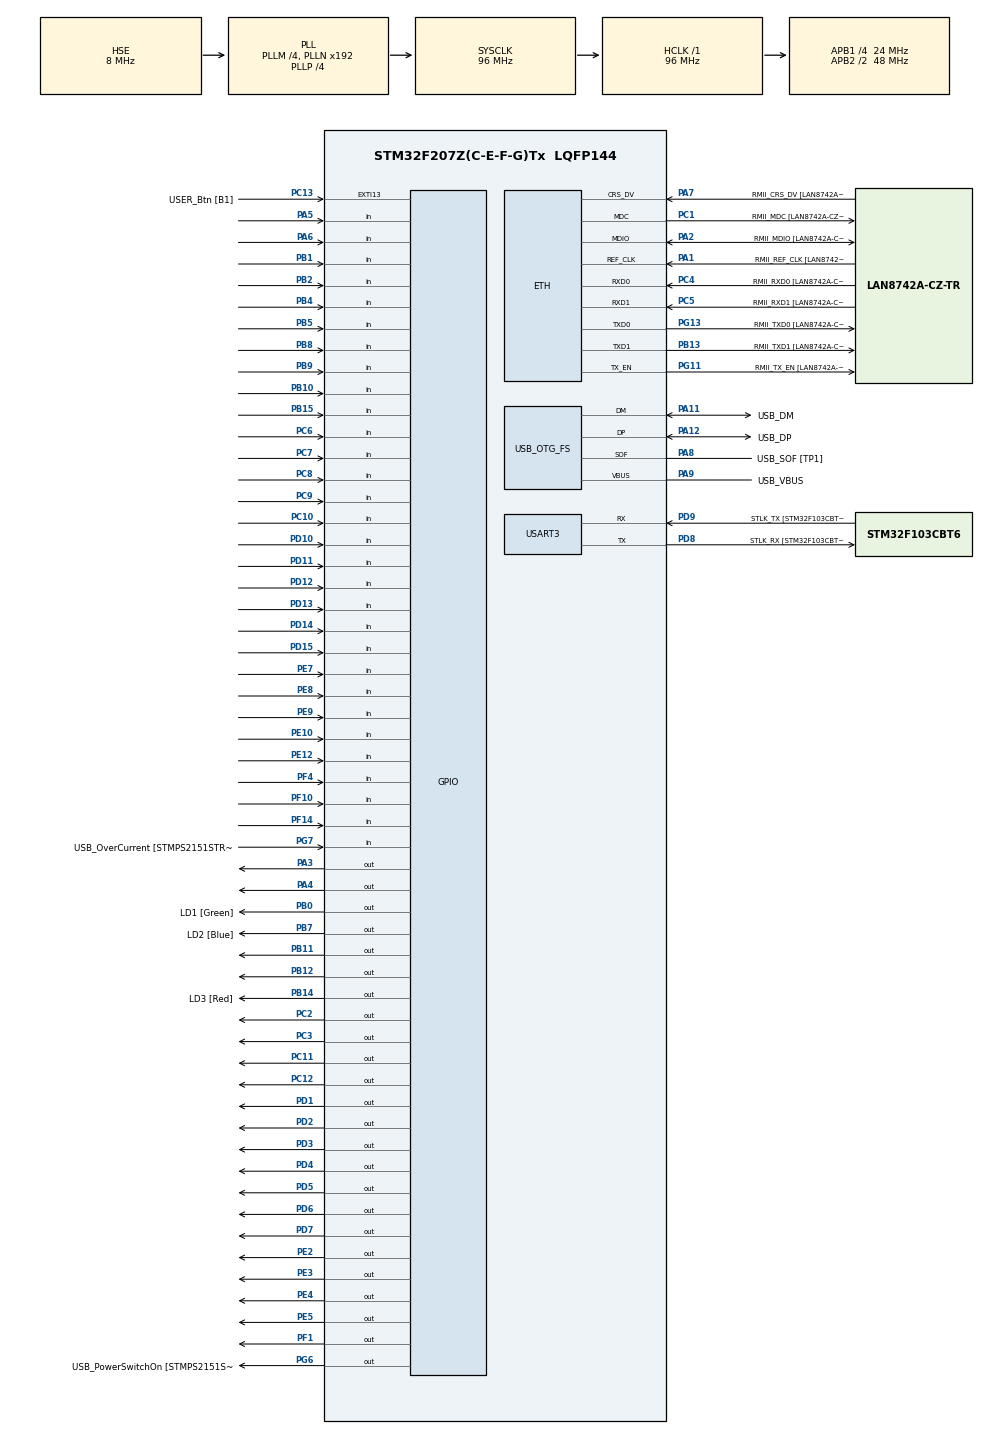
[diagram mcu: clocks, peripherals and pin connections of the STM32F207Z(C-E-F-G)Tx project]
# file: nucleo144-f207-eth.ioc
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ETH.MACAddr=00\:15\:7E\:00\:00\:00
ETH.MediaInterface=ETH_MEDIA_INTERFACE_RMII
ETH.PHY_Name=LAN8742A_PHY_ADDRESS
ETH.PHY_Value=0
ETH.PhyAddress=0
FREERTOS.Tasks01=defaultTask,0,512,StartDefaultTask,Default,NULL,Dynamic,NULL,NULL
FREERTOS.configMINIMAL_STACK_SIZE=256
FREERTOS.configUSE_NEWLIB_REENTRANT=1
LWIP.CMSIS_VERSION-Enabled=1
LWIP.GATEWAY_ADDRESS=000.000.000.000
LWIP.IP_ADDRESS=192.168.001.207
LWIP.LWIP_DHCP=0
LWIP.NETMASK_ADDRESS=255.255.255.000
LWIP.Version=v2.0.3_Cube
Mcu.Family=STM32F2
Mcu.Name=STM32F207Z(C-E-F-G)Tx
Mcu.Package=LQFP144
NVIC.ETH_IRQn=true\:5\:0\:false\:false\:true\:true\:false\:true
NVIC.PriorityGroup=NVIC_PRIORITYGROUP_4
NVIC.TIM1_UP_TIM10_IRQn=true\:15\:0\:false\:false\:true\:false\:false\:true
NVIC.TimeBase=TIM1_UP_TIM10_IRQn
NVIC.TimeBaseIP=TIM1
PA1.GPIO_Label=RMII_REF_CLK [LAN8742A-CZ-TR_REFCLK0]
PA1.Mode=RMII
PA1.Signal=ETH_REF_CLK
PA10.GPIO_Label=USB_ID
PA10.Signal=USB_OTG_FS_ID
PA11.GPIO_Label=USB_DM
PA11.Mode=Device_Only
PA11.Signal=USB_OTG_FS_DM
PA12.GPIO_Label=USB_DP
PA12.Mode=Device_Only
PA12.Signal=USB_OTG_FS_DP
PA13.GPIO_Label=TMS
PA13.Mode=Serial_Wire
PA13.Signal=SYS_JTMS-SWDIO
PA14.GPIO_Label=TCK
PA14.Mode=Serial_Wire
PA14.Signal=SYS_JTCK-SWCLK
PA2.GPIO_Label=RMII_MDIO [LAN8742A-CZ-TR_MDIO]
PA2.Mode=RMII
PA2.Signal=ETH_MDIO
PA3.Signal=GPIO_Output
PA4.Signal=GPIO_Output
PA5.GPIO_PuPd=GPIO_PULLDOWN
PA5.Signal=GPIO_Input
PA6.GPIO_PuPd=GPIO_PULLDOWN
PA6.Signal=GPIO_Input
PA7.GPIO_Label=RMII_CRS_DV [LAN8742A-CZ-TR_CRS_DV]
PA7.Mode=RMII
PA7.Signal=ETH_CRS_DV
PA8.GPIO_Label=USB_SOF [TP1]
PA8.Mode=Activate_SOF_FS
PA8.Signal=USB_OTG_FS_SOF
PA9.GPIO_Label=USB_VBUS
PA9.Mode=Activate_VBUS
PA9.Signal=USB_OTG_FS_VBUS
PB0.GPIO_Label=LD1 [Green]
PB0.Signal=GPIO_Output
PB1.GPIO_PuPd=GPIO_PULLDOWN
PB1.Signal=GPIO_Input
PB10.GPIO_PuPd=GPIO_PULLDOWN
PB10.Signal=GPIO_Input
PB11.Signal=GPIO_Output
PB12.Signal=GPIO_Output
PB13.GPIO_Label=RMII_TXD1 [LAN8742A-CZ-TR_TXD1]
PB13.Mode=RMII
PB13.Signal=ETH_TXD1
PB14.GPIO_Label=LD3 [Red]
PB14.Signal=GPIO_Output
PB15.GPIO_PuPd=GPIO_PULLDOWN
PB15.Signal=GPIO_Input
PB2.GPIO_PuPd=GPIO_PULLDOWN
PB2.Signal=GPIO_Input
PB3.GPIO_Label=SWO
PB3.Signal=SYS_JTDO-SWO
PB4.GPIO_PuPd=GPIO_PULLDOWN
PB4.Signal=GPIO_Input
PB5.GPIO_PuPd=GPIO_PULLDOWN
PB5.Signal=GPIO_Input
PB7.GPIO_Label=LD2 [Blue]
PB7.Signal=GPIO_Output
PB8.GPIO_PuPd=GPIO_PULLDOWN
PB8.Signal=GPIO_Input
PB9.GPIO_PuPd=GPIO_PULLDOWN
PB9.Signal=GPIO_Input
PC1.GPIO_Label=RMII_MDC [LAN8742A-CZ-TR_MDC]
PC1.Mode=RMII
PC1.Signal=ETH_MDC
PC10.GPIO_PuPd=GPIO_PULLDOWN
PC10.Signal=GPIO_Input
PC11.Signal=GPIO_Output
PC12.Signal=GPIO_Output
PC13.GPIO_Label=USER_Btn [B1]
PC13.Signal=GPXTI13
PC14-OSC32_IN.Mode=LSE-External-Oscillator
PC14-OSC32_IN.Signal=RCC_OSC32_IN
PC15-OSC32_OUT.Mode=LSE-External-Oscillator
PC15-OSC32_OUT.Signal=RCC_OSC32_OUT
PC2.Signal=GPIO_Output
PC3.Signal=GPIO_Output
PC4.GPIO_Label=RMII_RXD0 [LAN8742A-CZ-TR_RXD0]
PC4.Mode=RMII
PC4.Signal=ETH_RXD0
PC5.GPIO_Label=RMII_RXD1 [LAN8742A-CZ-TR_RXD1]
PC5.Mode=RMII
PC5.Signal=ETH_RXD1
PC6.GPIO_PuPd=GPIO_PULLDOWN
PC6.Signal=GPIO_Input
PC7.GPIO_PuPd=GPIO_PULLDOWN
PC7.Signal=GPIO_Input
PC8.GPIO_PuPd=GPIO_PULLDOWN
PC8.Signal=GPIO_Input
PC9.GPIO_PuPd=GPIO_PULLDOWN
PC9.Signal=GPIO_Input
PD1.Signal=GPIO_Output
PD10.GPIO_PuPd=GPIO_PULLDOWN
PD10.Signal=GPIO_Input
PD11.GPIO_PuPd=GPIO_PULLDOWN
PD11.Signal=GPIO_Input
PD12.GPIO_PuPd=GPIO_PULLDOWN
PD12.Signal=GPIO_Input
PD13.GPIO_PuPd=GPIO_PULLDOWN
PD13.Signal=GPIO_Input
PD14.GPIO_PuPd=GPIO_PULLDOWN
PD14.Signal=GPIO_Input
PD15.GPIO_PuPd=GPIO_PULLDOWN
PD15.Signal=GPIO_Input
PD2.Signal=GPIO_Output
PD3.Signal=GPIO_Output
PD4.Signal=GPIO_Output
PD5.Signal=GPIO_Output
PD6.Signal=GPIO_Output
PD7.Signal=GPIO_Output
PD8.GPIO_Label=STLK_RX [STM32F103CBT6_PA3]
PD8.Mode=Asynchronous
PD8.Signal=USART3_TX
PD9.GPIO_Label=STLK_TX [STM32F103CBT6_PA2]
PD9.Mode=Asynchronous
PD9.Signal=USART3_RX
PE10.GPIO_PuPd=GPIO_PULLDOWN
PE10.Signal=GPIO_Input
PE12.GPIO_PuPd=GPIO_PULLDOWN
PE12.Signal=GPIO_Input
PE2.Signal=GPIO_Output
PE3.Signal=GPIO_Output
PE4.Signal=GPIO_Output
PE5.Signal=GPIO_Output
PE7.GPIO_PuPd=GPIO_PULLDOWN
PE7.Signal=GPIO_Input
PE8.GPIO_PuPd=GPIO_PULLDOWN
PE8.Signal=GPIO_Input
PE9.GPIO_PuPd=GPIO_PULLDOWN
PE9.Signal=GPIO_Input
PF1.Signal=GPIO_Output
PF10.GPIO_PuPd=GPIO_PULLDOWN
PF10.Signal=GPIO_Input
PF14.GPIO_PuPd=GPIO_PULLDOWN
PF14.Signal=GPIO_Input
PF4.GPIO_PuPd=GPIO_PULLDOWN
PF4.Signal=GPIO_Input
PG11.GPIO_Label=RMII_TX_EN [LAN8742A-CZ-TR_TXEN]
PG11.Mode=RMII
PG11.Signal=ETH_TX_EN
PG13.GPIO_Label=RMII_TXD0 [LAN8742A-CZ-TR_TXD0]
PG13.Mode=RMII
PG13.Signal=ETH_TXD0
PG6.GPIO_Label=USB_PowerSwitchOn [STMPS2151STR_EN]
PG6.Signal=GPIO_Output
PG7.GPIO_Label=USB_OverCurrent [STMPS2151STR_FAULT]
PG7.Signal=GPIO_Input
PH0-OSC_IN.GPIO_Label=MCO [STM32F103CBT6_PA8]
PH0-OSC_IN.Mode=HSE-External-Clock-Source
PH0-OSC_IN.Signal=RCC_OSC_IN
PH1-OSC_OUT.Mode=HSE-External-Clock-Source
PH1-OSC_OUT.Signal=RCC_OSC_OUT
ProjectManager.HeapSize=0x200
ProjectManager.StackSize=0x400
ProjectManager.TargetToolchain=STM32CubeIDE
RCC.48MHZClocksFreq_Value=48000000
RCC.AHBFreq_Value=96000000
RCC.APB1CLKDivider=RCC_HCLK_DIV4
RCC.APB1Freq_Value=24000000
RCC.APB1TimFreq_Value=48000000
RCC.APB2CLKDivider=RCC_HCLK_DIV2
RCC.APB2Freq_Value=48000000
RCC.APB2TimFreq_Value=96000000
RCC.CortexFreq_Value=96000000
RCC.HCLKFreq_Value=96000000
RCC.HSE_VALUE=8000000
RCC.HSI_VALUE=16000000
RCC.PLLM=4
RCC.PLLMUL=RCC_PLL_MUL9
RCC.PLLP=RCC_PLLP_DIV4
RCC.PLLQ=8
RCC.PLLSourceVirtual=RCC_PLLSOURCE_HSE
RCC.PRESCALERUSB=RCC_USBCLKSOURCE_PLL_DIV1_5
RCC.SYSCLKFreq_VALUE=96000000
RCC.SYSCLKSource=RCC_SYSCLKSOURCE_PLLCLK
RCC.SYSCLKSourceVirtual=RCC_SYSCLKSOURCE_PLLCLK
RCC.USBFreq_Value=48000000
RCC.VCOOutputFreq_Value=384000000
USART3.VirtualMode=VM_ASYNC
USB_OTG_FS.VirtualMode=Device_Only
VP_FREERTOS_VS_CMSIS_V1.Mode=CMSIS_V1
VP_LWIP_VS_Enabled.Mode=Enabled
VP_SYS_VS_tim1.Mode=TIM1
board=NUCLEO-F207ZG

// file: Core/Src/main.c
/* USER CODE BEGIN Header */
/**
  ******************************************************************************
  * @file           : main.c
  * @brief          : Main program body
  ******************************************************************************
  * @attention
  *
  * <h2><center>&copy; Copyright (c) 2021 STMicroelectronics.
  * All rights reserved.</center></h2>
  *
  * This software component is licensed by ST under Ultimate Liberty license
  * SLA0044, the "License"; You may not use this file except in compliance with
  * the License. You may obtain a copy of the License at:
  *                             www.st.com/SLA0044
  *
  ******************************************************************************
  */
/* USER CODE END Header */
#include "main.h"
#include "cmsis_os.h"
#include "lwip.h"

UART_HandleTypeDef huart3;

PCD_HandleTypeDef hpcd_USB_OTG_FS;

osThreadId defaultTaskHandle;

void SystemClock_Config(void);
static void MX_GPIO_Init(void);
static void MX_USART3_UART_Init(void);
static void MX_USB_OTG_FS_PCD_Init(void);
void StartDefaultTask(void const * argument);

int main(void)
{

  /* MCU Configuration--------------------------------------------------------*/

  /* Reset of all peripherals, Initializes the Flash interface and the Systick. */
  HAL_Init();

  /* Configure the system clock */
  SystemClock_Config();

  /* Initialize all configured peripherals */
  MX_GPIO_Init();
  MX_USART3_UART_Init();
  MX_USB_OTG_FS_PCD_Init();

  /* Create the thread(s) */
  /* definition and creation of defaultTask */
  osThreadDef(defaultTask, StartDefaultTask, osPriorityNormal, 0, 512);
  defaultTaskHandle = osThreadCreate(osThread(defaultTask), NULL);

  /* Start scheduler */
  osKernelStart();

  /* We should never get here as control is now taken by the scheduler */
  /* Infinite loop */
  while (1)
  {

  }
}

void SystemClock_Config(void)
{
  RCC_OscInitTypeDef RCC_OscInitStruct = {0};
  RCC_ClkInitTypeDef RCC_ClkInitStruct = {0};

  /** Initializes the RCC Oscillators according to the specified parameters
  * in the RCC_OscInitTypeDef structure.
  */
  RCC_OscInitStruct.OscillatorType = RCC_OSCILLATORTYPE_HSE;
  RCC_OscInitStruct.HSEState = RCC_HSE_BYPASS;
  RCC_OscInitStruct.PLL.PLLState = RCC_PLL_ON;
  RCC_OscInitStruct.PLL.PLLSource = RCC_PLLSOURCE_HSE;
  RCC_OscInitStruct.PLL.PLLM = 4;
  RCC_OscInitStruct.PLL.PLLN = 192;
  RCC_OscInitStruct.PLL.PLLP = RCC_PLLP_DIV4;
  RCC_OscInitStruct.PLL.PLLQ = 8;
  if (HAL_RCC_OscConfig(&RCC_OscInitStruct) != HAL_OK)
  {
    Error_Handler();
  }
  /** Initializes the CPU, AHB and APB buses clocks
  */
  RCC_ClkInitStruct.ClockType = RCC_CLOCKTYPE_HCLK|RCC_CLOCKTYPE_SYSCLK
                              |RCC_CLOCKTYPE_PCLK1|RCC_CLOCKTYPE_PCLK2;
  RCC_ClkInitStruct.SYSCLKSource = RCC_SYSCLKSOURCE_PLLCLK;
  RCC_ClkInitStruct.AHBCLKDivider = RCC_SYSCLK_DIV1;
  RCC_ClkInitStruct.APB1CLKDivider = RCC_HCLK_DIV4;
  RCC_ClkInitStruct.APB2CLKDivider = RCC_HCLK_DIV2;

  if (HAL_RCC_ClockConfig(&RCC_ClkInitStruct, FLASH_LATENCY_3) != HAL_OK)
  {
    Error_Handler();
  }
}

static void MX_USART3_UART_Init(void)
{

  huart3.Instance = USART3;
  huart3.Init.BaudRate = 115200;
  huart3.Init.WordLength = UART_WORDLENGTH_8B;
  huart3.Init.StopBits = UART_STOPBITS_1;
  huart3.Init.Parity = UART_PARITY_NONE;
  huart3.Init.Mode = UART_MODE_TX_RX;
  huart3.Init.HwFlowCtl = UART_HWCONTROL_NONE;
  huart3.Init.OverSampling = UART_OVERSAMPLING_16;
  if (HAL_UART_Init(&huart3) != HAL_OK)
  {
    Error_Handler();
  }

}

static void MX_USB_OTG_FS_PCD_Init(void)
{

  hpcd_USB_OTG_FS.Instance = USB_OTG_FS;
  hpcd_USB_OTG_FS.Init.dev_endpoints = 4;
  hpcd_USB_OTG_FS.Init.speed = PCD_SPEED_FULL;
  hpcd_USB_OTG_FS.Init.dma_enable = DISABLE;
  hpcd_USB_OTG_FS.Init.phy_itface = PCD_PHY_EMBEDDED;
  hpcd_USB_OTG_FS.Init.Sof_enable = ENABLE;
  hpcd_USB_OTG_FS.Init.low_power_enable = DISABLE;
  hpcd_USB_OTG_FS.Init.vbus_sensing_enable = ENABLE;
  hpcd_USB_OTG_FS.Init.use_dedicated_ep1 = DISABLE;
  if (HAL_PCD_Init(&hpcd_USB_OTG_FS) != HAL_OK)
  {
    Error_Handler();
  }

}

static void MX_GPIO_Init(void)
{
  GPIO_InitTypeDef GPIO_InitStruct = {0};

  /* GPIO Ports Clock Enable */
  __HAL_RCC_GPIOE_CLK_ENABLE();
  __HAL_RCC_GPIOC_CLK_ENABLE();
  __HAL_RCC_GPIOF_CLK_ENABLE();
  __HAL_RCC_GPIOH_CLK_ENABLE();
  __HAL_RCC_GPIOA_CLK_ENABLE();
  __HAL_RCC_GPIOB_CLK_ENABLE();
  __HAL_RCC_GPIOD_CLK_ENABLE();
  __HAL_RCC_GPIOG_CLK_ENABLE();

  /*Configure GPIO pin Output Level */
  HAL_GPIO_WritePin(GPIOE, GPIO_PIN_2|GPIO_PIN_3|GPIO_PIN_4|GPIO_PIN_5, GPIO_PIN_RESET);

  /*Configure GPIO pin Output Level */
  HAL_GPIO_WritePin(GPIOF, GPIO_PIN_1, GPIO_PIN_RESET);

  /*Configure GPIO pin Output Level */
  HAL_GPIO_WritePin(GPIOC, GPIO_PIN_2|GPIO_PIN_3|GPIO_PIN_11|GPIO_PIN_12, GPIO_PIN_RESET);

  /*Configure GPIO pin Output Level */
  HAL_GPIO_WritePin(GPIOA, GPIO_PIN_3|GPIO_PIN_4, GPIO_PIN_RESET);

  /*Configure GPIO pin Output Level */
  HAL_GPIO_WritePin(GPIOB, LD1_Pin|GPIO_PIN_11|GPIO_PIN_12|LD3_Pin
                          |LD2_Pin, GPIO_PIN_RESET);

  /*Configure GPIO pin Output Level */
  HAL_GPIO_WritePin(USB_PowerSwitchOn_GPIO_Port, USB_PowerSwitchOn_Pin, GPIO_PIN_RESET);

  /*Configure GPIO pin Output Level */
  HAL_GPIO_WritePin(GPIOD, GPIO_PIN_1|GPIO_PIN_2|GPIO_PIN_3|GPIO_PIN_4
                          |GPIO_PIN_5|GPIO_PIN_6|GPIO_PIN_7, GPIO_PIN_RESET);

  /*Configure GPIO pins : PE2 PE3 PE4 PE5 */
  GPIO_InitStruct.Pin = GPIO_PIN_2|GPIO_PIN_3|GPIO_PIN_4|GPIO_PIN_5;
  GPIO_InitStruct.Mode = GPIO_MODE_OUTPUT_PP;
  GPIO_InitStruct.Pull = GPIO_NOPULL;
  GPIO_InitStruct.Speed = GPIO_SPEED_FREQ_LOW;
  HAL_GPIO_Init(GPIOE, &GPIO_InitStruct);

  /*Configure GPIO pin : USER_Btn_Pin */
  GPIO_InitStruct.Pin = USER_Btn_Pin;
  GPIO_InitStruct.Mode = GPIO_MODE_IT_RISING;
  GPIO_InitStruct.Pull = GPIO_NOPULL;
  HAL_GPIO_Init(USER_Btn_GPIO_Port, &GPIO_InitStruct);

  /*Configure GPIO pin : PF1 */
  GPIO_InitStruct.Pin = GPIO_PIN_1;
  GPIO_InitStruct.Mode = GPIO_MODE_OUTPUT_PP;
  GPIO_InitStruct.Pull = GPIO_NOPULL;
  GPIO_InitStruct.Speed = GPIO_SPEED_FREQ_LOW;
  HAL_GPIO_Init(GPIOF, &GPIO_InitStruct);

  /*Configure GPIO pins : PF4 PF10 PF14 */
  GPIO_InitStruct.Pin = GPIO_PIN_4|GPIO_PIN_10|GPIO_PIN_14;
  GPIO_InitStruct.Mode = GPIO_MODE_INPUT;
  GPIO_InitStruct.Pull = GPIO_PULLDOWN;
  HAL_GPIO_Init(GPIOF, &GPIO_InitStruct);

  /*Configure GPIO pins : PC2 PC3 PC11 PC12 */
  GPIO_InitStruct.Pin = GPIO_PIN_2|GPIO_PIN_3|GPIO_PIN_11|GPIO_PIN_12;
  GPIO_InitStruct.Mode = GPIO_MODE_OUTPUT_PP;
  GPIO_InitStruct.Pull = GPIO_NOPULL;
  GPIO_InitStruct.Speed = GPIO_SPEED_FREQ_LOW;
  HAL_GPIO_Init(GPIOC, &GPIO_InitStruct);

  /*Configure GPIO pins : PA3 PA4 */
  GPIO_InitStruct.Pin = GPIO_PIN_3|GPIO_PIN_4;
  GPIO_InitStruct.Mode = GPIO_MODE_OUTPUT_PP;
  GPIO_InitStruct.Pull = GPIO_NOPULL;
  GPIO_InitStruct.Speed = GPIO_SPEED_FREQ_LOW;
  HAL_GPIO_Init(GPIOA, &GPIO_InitStruct);

  /*Configure GPIO pins : PA5 PA6 */
  GPIO_InitStruct.Pin = GPIO_PIN_5|GPIO_PIN_6;
  GPIO_InitStruct.Mode = GPIO_MODE_INPUT;
  GPIO_InitStruct.Pull = GPIO_PULLDOWN;
  HAL_GPIO_Init(GPIOA, &GPIO_InitStruct);

  /*Configure GPIO pins : LD1_Pin PB11 PB12 LD3_Pin
                           LD2_Pin */
  GPIO_InitStruct.Pin = LD1_Pin|GPIO_PIN_11|GPIO_PIN_12|LD3_Pin
                          |LD2_Pin;
  GPIO_InitStruct.Mode = GPIO_MODE_OUTPUT_PP;
  GPIO_InitStruct.Pull = GPIO_NOPULL;
  GPIO_InitStruct.Speed = GPIO_SPEED_FREQ_LOW;
  HAL_GPIO_Init(GPIOB, &GPIO_InitStruct);

  /*Configure GPIO pins : PB1 PB2 PB10 PB15
                           PB4 PB5 PB8 PB9 */
  GPIO_InitStruct.Pin = GPIO_PIN_1|GPIO_PIN_2|GPIO_PIN_10|GPIO_PIN_15
                          |GPIO_PIN_4|GPIO_PIN_5|GPIO_PIN_8|GPIO_PIN_9;
  GPIO_InitStruct.Mode = GPIO_MODE_INPUT;
  GPIO_InitStruct.Pull = GPIO_PULLDOWN;
  HAL_GPIO_Init(GPIOB, &GPIO_InitStruct);

  /*Configure GPIO pins : PE7 PE8 PE9 PE10
                           PE12 */
  GPIO_InitStruct.Pin = GPIO_PIN_7|GPIO_PIN_8|GPIO_PIN_9|GPIO_PIN_10
                          |GPIO_PIN_12;
  GPIO_InitStruct.Mode = GPIO_MODE_INPUT;
  GPIO_InitStruct.Pull = GPIO_PULLDOWN;
  HAL_GPIO_Init(GPIOE, &GPIO_InitStruct);

  /*Configure GPIO pins : PD10 PD11 PD12 PD13
                           PD14 PD15 */
  GPIO_InitStruct.Pin = GPIO_PIN_10|GPIO_PIN_11|GPIO_PIN_12|GPIO_PIN_13
                          |GPIO_PIN_14|GPIO_PIN_15;
  GPIO_InitStruct.Mode = GPIO_MODE_INPUT;
  GPIO_InitStruct.Pull = GPIO_PULLDOWN;
  HAL_GPIO_Init(GPIOD, &GPIO_InitStruct);

  /*Configure GPIO pin : USB_PowerSwitchOn_Pin */
  GPIO_InitStruct.Pin = USB_PowerSwitchOn_Pin;
  GPIO_InitStruct.Mode = GPIO_MODE_OUTPUT_PP;
  GPIO_InitStruct.Pull = GPIO_NOPULL;
  GPIO_InitStruct.Speed = GPIO_SPEED_FREQ_LOW;
  HAL_GPIO_Init(USB_PowerSwitchOn_GPIO_Port, &GPIO_InitStruct);

  /*Configure GPIO pin : USB_OverCurrent_Pin */
  GPIO_InitStruct.Pin = USB_OverCurrent_Pin;
  GPIO_InitStruct.Mode = GPIO_MODE_INPUT;
  GPIO_InitStruct.Pull = GPIO_NOPULL;
  HAL_GPIO_Init(USB_OverCurrent_GPIO_Port, &GPIO_InitStruct);

  /*Configure GPIO pins : PC6 PC7 PC8 PC9
                           PC10 */
  GPIO_InitStruct.Pin = GPIO_PIN_6|GPIO_PIN_7|GPIO_PIN_8|GPIO_PIN_9
                          |GPIO_PIN_10;
  GPIO_InitStruct.Mode = GPIO_MODE_INPUT;
  GPIO_InitStruct.Pull = GPIO_PULLDOWN;
  HAL_GPIO_Init(GPIOC, &GPIO_InitStruct);

  /*Configure GPIO pins : PD1 PD2 PD3 PD4
                           PD5 PD6 PD7 */
  GPIO_InitStruct.Pin = GPIO_PIN_1|GPIO_PIN_2|GPIO_PIN_3|GPIO_PIN_4
                          |GPIO_PIN_5|GPIO_PIN_6|GPIO_PIN_7;
  GPIO_InitStruct.Mode = GPIO_MODE_OUTPUT_PP;
  GPIO_InitStruct.Pull = GPIO_NOPULL;
  GPIO_InitStruct.Speed = GPIO_SPEED_FREQ_LOW;
  HAL_GPIO_Init(GPIOD, &GPIO_InitStruct);

}

void StartDefaultTask(void const * argument)
{
  /* init code for LWIP */
  MX_LWIP_Init();
  /* USER CODE BEGIN 5 */
  /* Infinite loop */
  app_echoserver_init();
  for(;;)
  {
	  MX_LWIP_Process();
    osDelay(1);
  }
  /* USER CODE END 5 */
}

void HAL_TIM_PeriodElapsedCallback(TIM_HandleTypeDef *htim)
{
  if (htim->Instance == TIM1) {
    HAL_IncTick();
  }
}

void Error_Handler(void)
{
  __disable_irq();
  while (1)
  {
  }
}

/************************ (C) COPYRIGHT STMicroelectronics *****END OF FILE****/
